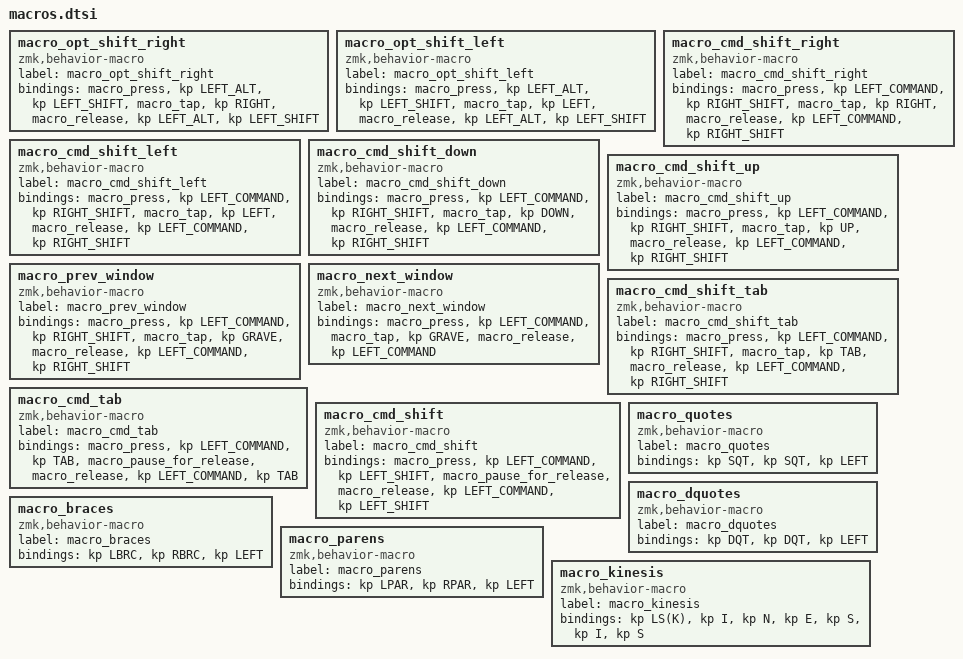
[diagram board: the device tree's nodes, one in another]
macro_opt_shift_right: macro_opt_shift_right{
compatible = "zmk,behavior-macro";
label = "macro_opt_shift_right";
#binding-cells = <0>;
bindings
  = <&macro_press &kp LEFT_ALT &kp LEFT_SHIFT>
  , <&macro_tap &kp RIGHT>
  , <&macro_release &kp LEFT_ALT &kp LEFT_SHIFT>;
};
macro_opt_shift_left: macro_opt_shift_left{
compatible = "zmk,behavior-macro";
label = "macro_opt_shift_left";
#binding-cells = <0>;
bindings
  = <&macro_press &kp LEFT_ALT &kp LEFT_SHIFT>
  , <&macro_tap &kp LEFT>
  , <&macro_release &kp LEFT_ALT &kp LEFT_SHIFT>;
};
macro_cmd_shift_right: macro_cmd_shift_right{
compatible = "zmk,behavior-macro";
label = "macro_cmd_shift_right";
#binding-cells = <0>;
bindings
  = <&macro_press &kp LEFT_COMMAND &kp RIGHT_SHIFT>
  , <&macro_tap &kp RIGHT>
  , <&macro_release &kp LEFT_COMMAND &kp RIGHT_SHIFT>;
};
macro_cmd_shift_left: macro_cmd_shift_left{
compatible = "zmk,behavior-macro";
label = "macro_cmd_shift_left";
#binding-cells = <0>;
bindings
  = <&macro_press &kp LEFT_COMMAND &kp RIGHT_SHIFT>
  , <&macro_tap &kp LEFT>
  , <&macro_release &kp LEFT_COMMAND &kp RIGHT_SHIFT>;
};
macro_cmd_shift_down: macro_cmd_shift_down{
compatible = "zmk,behavior-macro";
label = "macro_cmd_shift_down";
#binding-cells = <0>;
bindings
  = <&macro_press &kp LEFT_COMMAND &kp RIGHT_SHIFT>
  , <&macro_tap &kp DOWN>
  , <&macro_release &kp LEFT_COMMAND &kp RIGHT_SHIFT>;
};
macro_cmd_shift_up: macro_cmd_shift_up{
compatible = "zmk,behavior-macro";
label = "macro_cmd_shift_up";
#binding-cells = <0>;
bindings
  = <&macro_press &kp LEFT_COMMAND &kp RIGHT_SHIFT>
  , <&macro_tap &kp UP>
  , <&macro_release &kp LEFT_COMMAND &kp RIGHT_SHIFT>;
};
macro_prev_window: macro_prev_window{
compatible = "zmk,behavior-macro";
label = "macro_prev_window";
#binding-cells = <0>;
bindings
  = <&macro_press &kp LEFT_COMMAND &kp RIGHT_SHIFT>
  , <&macro_tap &kp GRAVE>
  , <&macro_release &kp LEFT_COMMAND &kp RIGHT_SHIFT>;
};
macro_next_window: macro_next_window{
compatible = "zmk,behavior-macro";
label = "macro_next_window";
#binding-cells = <0>;
bindings
  = <&macro_press &kp LEFT_COMMAND>
  , <&macro_tap &kp GRAVE>
  , <&macro_release &kp LEFT_COMMAND>;
};
macro_cmd_shift_tab: macro_cmd_shift_tab{
compatible = "zmk,behavior-macro";
label = "macro_cmd_shift_tab";
#binding-cells = <0>;
bindings
  = <&macro_press &kp LEFT_COMMAND &kp RIGHT_SHIFT>
  , <&macro_tap &kp TAB>
  , <&macro_release &kp LEFT_COMMAND &kp RIGHT_SHIFT>;
};
macro_cmd_tab: macro_cmd_tab{
compatible = "zmk,behavior-macro";
label = "macro_cmd_tab";
#binding-cells = <0>;
bindings
  = <&macro_press &kp LEFT_COMMAND &kp TAB>
  , <&macro_pause_for_release>
  , <&macro_release &kp LEFT_COMMAND &kp TAB>;
};
macro_cmd_shift: macro_cmd_shift{
compatible = "zmk,behavior-macro";
label = "macro_cmd_shift";
#binding-cells = <0>;
bindings
  = <&macro_press &kp LEFT_COMMAND &kp LEFT_SHIFT>
  , <&macro_pause_for_release>
  , <&macro_release &kp LEFT_COMMAND &kp LEFT_SHIFT>;
};
macro_quotes: macro_quotes{
compatible = "zmk,behavior-macro";
label = "macro_quotes";
#binding-cells = <0>;
bindings = <&kp SQT>, <&kp SQT>, <&kp LEFT>;
};
macro_dquotes: macro_dquotes{
compatible = "zmk,behavior-macro";
label = "macro_dquotes";
#binding-cells = <0>;
bindings = <&kp DQT>, <&kp DQT>, <&kp LEFT>;
};
macro_braces: macro_braces{
compatible = "zmk,behavior-macro";
label = "macro_braces";
#binding-cells = <0>;
bindings = <&kp LBRC>, <&kp RBRC>, <&kp LEFT>;
};
macro_parens: macro_parens{
compatible = "zmk,behavior-macro";
label = "macro_parens";
#binding-cells = <0>;
bindings = <&kp LPAR>, <&kp RPAR>, <&kp LEFT>;
};
macro_kinesis: macro_kinesis{
compatible = "zmk,behavior-macro";
label = "macro_kinesis";
#binding-cells = <0>;
bindings = <&kp LS(K)>, <&kp I>, <&kp N>, <&kp E>, <&kp S>, <&kp I>, <&kp S>;
};
